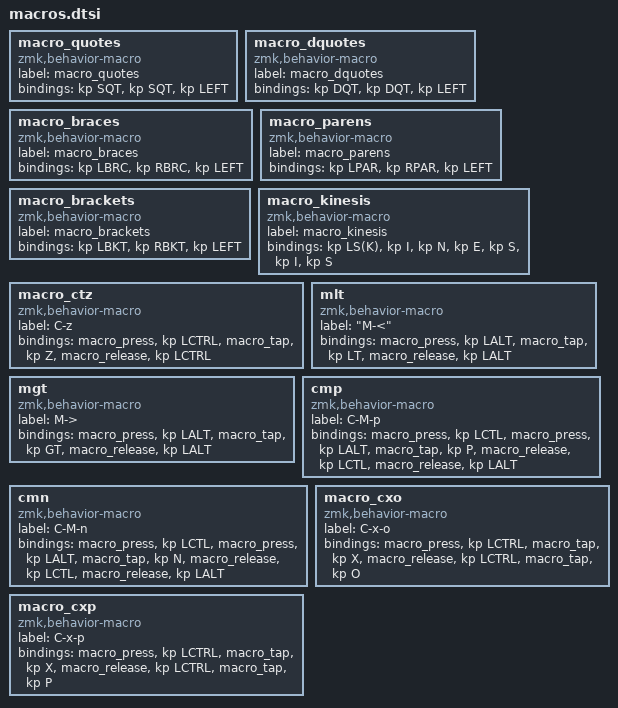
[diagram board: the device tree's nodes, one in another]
  macro_quotes: macro_quotes {
    compatible = "zmk,behavior-macro";
    label = "macro_quotes";
    #binding-cells = <0>;
    bindings = <&kp SQT>, <&kp SQT>, <&kp LEFT>;
  };
  macro_dquotes: macro_dquotes {
    compatible = "zmk,behavior-macro";
    label = "macro_dquotes";
    #binding-cells = <0>;
    bindings = <&kp DQT>, <&kp DQT>, <&kp LEFT>;
  };
  macro_braces: macro_braces {
    compatible = "zmk,behavior-macro";
    label = "macro_braces";
    #binding-cells = <0>;
    bindings = <&kp LBRC>, <&kp RBRC>, <&kp LEFT>;
  };
  macro_parens: macro_parens {
    compatible = "zmk,behavior-macro";
    label = "macro_parens";
    #binding-cells = <0>;
    bindings = <&kp LPAR>, <&kp RPAR>, <&kp LEFT>;
  };
  macro_brackets: macro_brackets {
    compatible = "zmk,behavior-macro";
    label = "macro_brackets";
    #binding-cells = <0>;
    bindings = <&kp LBKT>, <&kp RBKT>, <&kp LEFT>;
  };
  macro_kinesis: macro_kinesis {
    compatible = "zmk,behavior-macro";
    label = "macro_kinesis";
    #binding-cells = <0>;
    bindings = <&kp LS(K)>, <&kp I>, <&kp N>, <&kp E>, <&kp S>, <&kp I>, <&kp S>;
  };

macro_ctz: macro_ctz {
    label = "C-z";
    compatible = "zmk,behavior-macro";
    #binding-cells = <0>;
    bindings
	= <&macro_press &kp LCTRL>
	, <&macro_tap &kp Z>
	, <&macro_release &kp LCTRL>
	;
};

mlt: mlt {
label = "M-<";
    compatible = "zmk,behavior-macro";
    #binding-cells = <0>;
    bindings
	= <&macro_press &kp LALT>
	, <&macro_tap &kp LT>
	, <&macro_release &kp LALT>
	;
};
mgt: mgt {
    label = "M->";
    compatible = "zmk,behavior-macro";
    #binding-cells = <0>;
    bindings
	= <&macro_press &kp LALT>
	, <&macro_tap &kp GT>
	, <&macro_release &kp LALT>
	;
};

cmp: cmp {
    label = "C-M-p";
    compatible = "zmk,behavior-macro";
    #binding-cells = <0>;
    bindings
      = <&macro_press &kp LCTL>
      , <&macro_press &kp LALT>
      , <&macro_tap &kp P>
      , <&macro_release &kp LCTL>
      , <&macro_release &kp LALT>
      ;
};
cmn: cmn {
    label = "C-M-n";
    compatible = "zmk,behavior-macro";
    #binding-cells = <0>;
    bindings
      = <&macro_press &kp LCTL>
      , <&macro_press &kp LALT>
      , <&macro_tap &kp N>
      , <&macro_release &kp LCTL>
      , <&macro_release &kp LALT>
      ;
};
macro_cxo: macro_cxo {
    label = "C-x-o";
    compatible = "zmk,behavior-macro";
    #binding-cells = <0>;
    bindings
	= <&macro_press &kp LCTRL>
	, <&macro_tap &kp X>
	, <&macro_release &kp LCTRL>
        , <&macro_tap &kp O>
	;
};
macro_cxp: macro_cxp {
    label = "C-x-p";
    compatible = "zmk,behavior-macro";
    #binding-cells = <0>;
    bindings
	= <&macro_press &kp LCTRL>
	, <&macro_tap &kp X>
	, <&macro_release &kp LCTRL>
        , <&macro_tap &kp P>
	;
};
